# STM32G431C6T6 register map
File version: 1.0
STM32G431C6T6,STM32G431C6U6,STM32G431C8T3,STM32G431C8T6,STM32G431C8T7,STM32G431C8U3,STM32G431C8U6,STM32G431C8U7,STM32G431CBT3,STM32G431CBT6,STM32G431CBT7,STM32G431CBU3,STM32G431CBU6,STM32G431CBU7,STM32G431CBY3,STM32G431CBY6,STM32G431CBY7,STM32G431K6T3,STM32G431K6T6,STM32G431K6T7,STM32G431K6U3,STM32G431K6U6,STM32G431K6U7,STM32G431K8T3,STM32G431K8T6,STM32G431K8T7,STM32G431K8U3,STM32G431K8U6,STM32G431K8U7,STM32G431KBT3,STM32G431KBT6,STM32G431KBT7,STM32G431KBU3,STM32G431KBU6,STM32G431KBU7,STM32G431M6T6,STM32G431M8T6,STM32G431MBT3,STM32G431MBT6,STM32G431MBT7,STM32G431R6I6,STM32G431R6T6,STM32G431R8I6,STM32G431R8T6,STM32G431RBI3,STM32G431RBI6,STM32G431RBI7,STM32G431RBT3,STM32G431RBT6,STM32G431RBT7,STM32G431V6T6,STM32G431V8T6,STM32G431VBT3,STM32G431VBT6,STM32G431VBT7,STM32G441CBT3,STM32G441CBT6,STM32G441CBT7,STM32G441CBU3,STM32G441CBU6,STM32G441CBU7,STM32G441CBY3,STM32G441CBY6,STM32G441CBY7,STM32G441KBT3,STM32G441KBT6,STM32G441KBT7,STM32G441KBU3,STM32G441KBU6,STM32G441KBU7,STM32G441MBT6,STM32G441RBI3,STM32G441RBI6,STM32G441RBI7,STM32G441RBT3,STM32G441RBT6,STM32G441RBT7,STM32G441VBT3,STM32G441VBT6,STM32G441VBT7,STM32G471CCT6,STM32G471CCU3,STM32G471CCU6,STM32G471CCU7,STM32G471CET3,STM32G471CET6,STM32G471CET7,STM32G471CEU3,STM32G471CEU6,STM32G471CEU7,STM32G471MCT6,STM32G471MET3,STM32G471MET6,STM32G471MET7,STM32G471MEY6,STM32G471QCT6,STM32G471QET6,STM32G471RCT6,STM32G471RET3,STM32G471RET6,STM32G471RET7,STM32G471VCH6,STM32G471VCI6,STM32G471VCT6,STM32G471VEH3,STM32G471VEH6,STM32G471VEH7,ST
Registers are 32-bit, access not given, reset 0x0 unless marked. A register's access mark holds for its fields unless they carry their own. Offsets are from the block's base; lines under a group give offsets from that group; [hi:lo] are bit positions; {n}, {i} and the like mark numbered series; 'fields as' and 'values as' point back to an identical list; <NAME> marks a mode.

## Memory map
0x40000000 TIM2
0x40000400 TIM3
0x40000800 TIM4
0x40000C00 TIM5
0x40001000 TIM6
0x40001400 TIM7
0x40002000 CRS
0x40002400 TAMP
0x40002800 BKP
0x40002800 RTC
0x40002C00 WWDG
0x40003000 IWDG
0x40003800 SPI2
0x40003C00 SPI3
0x40004400 USART2
0x40004800 USART3
0x40004C00 UART4
0x40005000 UART5
0x40005400 I2C1
0x40005800 I2C2
0x40005C00 USBFS
0x40006400 FDCAN1
0x40006800 FDCAN2
0x40006C00 FDCAN3
0x40007000 PWR
0x40007800 I2C3
0x40007C00 LPTIM1
0x40008000 LPUART1
0x40008400 I2C4
0x4000A000 UCPD1
0x4000A400 FDCANMRAM
0x4000A800 FDCANMRAM
0x4000AC00 FDCANMRAM
0x40010000 SYSCFG
0x40010030 VREFBUF
0x40010200 COMP
0x40010300 OPAMP
0x40010400 EXTI
0x40012C00 TIM1
0x40013000 SPI1
0x40013400 TIM8
0x40013800 USART1
0x40013C00 SPI4
0x40014000 TIM15
0x40014400 TIM16
0x40014800 TIM17
0x40015000 TIM20
0x40015400 SAI1
0x40016800 HRTIM
0x40020000 DMA1
0x40020400 DMA2
0x40020800 DMAMUX
0x40020C00 CORDIC
0x40021000 RCC
0x40021400 FMAC
0x40022000 FLASH
0x40023000 CRC
0x48000000 GPIOA
0x48000400 GPIOB
0x48000800 GPIOC
0x48000C00 GPIOD
0x48001000 GPIOE
0x48001400 GPIOF
0x48001800 GPIOG
0x50000000 ADC1
0x50000100 ADC2
0x50000400 ADC3
0x50000500 ADC4
0x50000700 ADC5
0x50000800 DAC1
0x50000C00 DAC2
0x50001000 DAC3
0x50001400 DAC4
0x50060000 AES
0x50060800 RNG
0xA0000000 FSMC
0xA0001000 QUADSPI

## TIM2
Base 0x40000000
Same registers: TIM3 0x40000400, TIM4 0x40000800, TIM5 0x40000C00
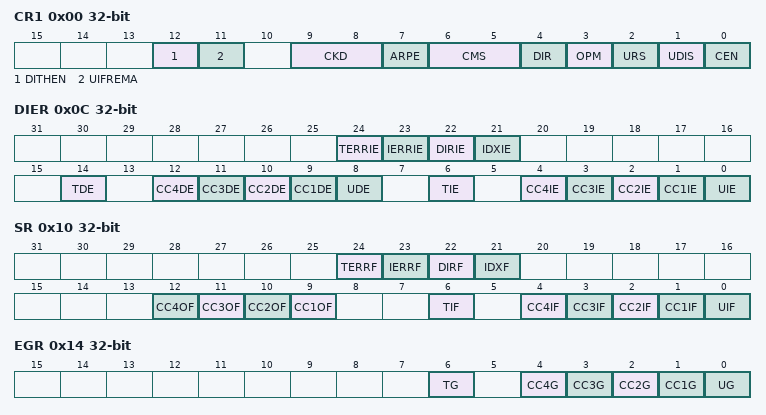
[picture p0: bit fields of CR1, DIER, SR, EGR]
0x00 CR1
  [12] DITHEN, [11] UIFREMA, [9:8] CKD, [7] ARPE, [6:5] CMS, [4] DIR, [3] OPM, [2] URS, [1] UDIS, [0] CEN
0x04 CR2
  [7] TI1S, [25:4] MMS, [3] CCDS
0x08 SMCR
  [25] SMSPS, [24] SMSPE, [15] ETP, [14] ECE, [13:12] ETPS, [11:8] ETF, [7] MSM, [21:4] TS, [16:0] SMS
0x0C DIER
  [24] TERRIE, [23] IERRIE, [22] DIRIE, [21] IDXIE, [14] TDE, [n+8] CC{n}DE (n=1..4), [8] UDE, [6] TIE, [n] CC{n}IE (n=1..4), [0] UIE
0x10 SR
  [24] TERRF, [23] IERRF, [22] DIRF, [21] IDXF, [n+8] CC{n}OF (n=1..4), [6] TIF, [n] CC{n}IF (n=1..4), [0] UIF
0x14 EGR
  [6] TG, [n] CC{n}G (n=1..4), [0] UG
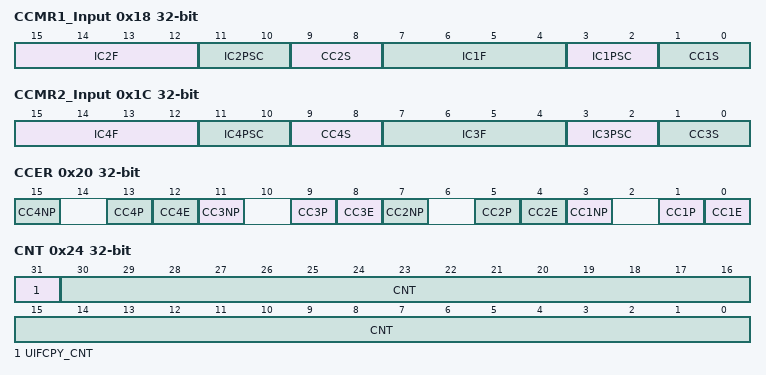
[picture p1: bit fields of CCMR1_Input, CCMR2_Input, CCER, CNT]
0x18 CCMR1_Input
  [15:12] IC2F, [11:10] IC2PSC, [9:8] CC2S, [7:4] IC1F, [3:2] IC1PSC, [1:0] CC1S
0x18 CCMR1_Output
  [15] OC2CE, [24:12] OC2M, [11] OC2PE, [10] OC2FE, [9:8] CC2S, [7] OC1CE, [16:4] OC1M, [3] OC1PE, [2] OC1FE, [1:0] CC1S
0x1C CCMR2_Input
  [15:12] IC4F, [11:10] IC4PSC, [9:8] CC4S, [7:4] IC3F, [3:2] IC3PSC, [1:0] CC3S
0x1C CCMR2_Output
  [15] O24CE, [24:12] OC4M, [11] OC4PE, [10] OC4FE, [9:8] CC4S, [7] OC3CE, [16:4] OC3M, [3] OC3PE, [2] OC3FE, [1:0] CC3S
0x20 CCER
  [4n-1] CC{n}NP (n=1..4), [4n-3] CC{n}P (n=1..4), [4n-4] CC{n}E (n=1..4)
0x24 CNT
  [31] UIFCPY_CNT, [30:0] CNT
0x28 PSC
  [15:0] PSC
0x2C ARR
{0x30+4i} CCR{i} (i=1..4)
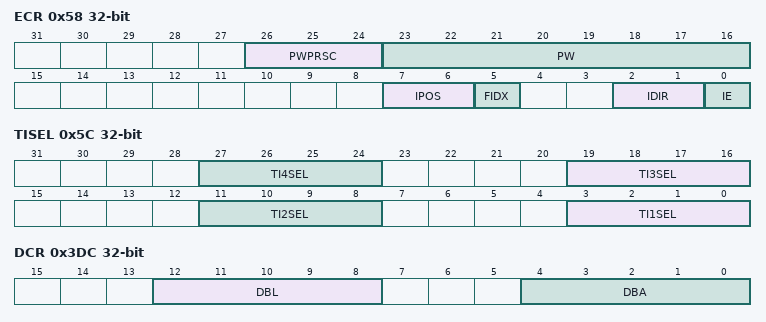
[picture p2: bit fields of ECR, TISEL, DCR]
0x58 ECR
  [26:24] PWPRSC, [23:16] PW, [7:6] IPOS, [5] FIDX, [2:1] IDIR, [0] IE
0x5C TISEL
  [8n-5:8n-8] TI{n}SEL (n=1..4)
0x60 AF1
  [17:14] ETRSEL
0x64 AF2
  [18:16] OCRSEL
0x3DC DCR
  [12:8] DBL, [4:0] DBA
0x3E0 DMAR
  [31:0] DMAB
